# NUC200AE_v1 register map
File version: 1.0
Registers are 32-bit, read-write, reset 0x0 unless marked. A register's access mark holds for its fields unless they carry their own. Offsets are from the block's base; [hi:lo] are bit positions; 'fields as' and 'values as' point back to an identical list.

## WWDT — WWDT Register Map
Base 0x40004100
0x00 WWDTRLD wo — Window Watchdog Timer Reload Counter Register
  [31:0] WWDTRLD — WWDT Reload Counter Register. Writing 0x00005AA5 to this register will reload the WWDT counter value to 0x3F. Note: User can only write WWDTRLD to reload WWDT counter value when current WWDT counter value between 0 and WINCMP. If user writes WWDTRLD when current WWDT counter value is larger than WINCMP, WWDT reset signal will generate immediately.
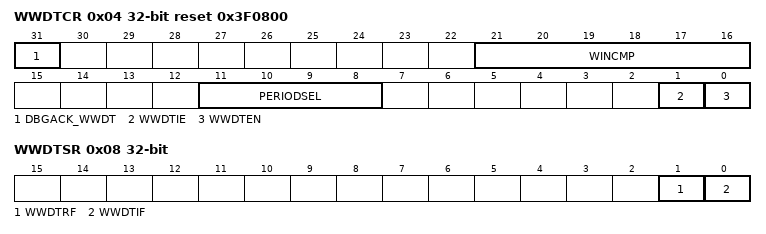
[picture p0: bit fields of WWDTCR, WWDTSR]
0x04 WWDTCR reset 0x3F0800 — Window Watchdog Timer Control Register
  [31] DBGACK_WWDT — ICE Debug Mode Acknowledge Disable Bit. WWDT down counter will keep going no matter CPU is held by ICE or not.
    0=ICE debug mode acknowledgement effects WWDT counting; 1=ICE debug mode acknowledgement Disabled
  [21:16] WINCMP — WWDT Window Compare Register. Set this register to adjust the valid reload window. Note: User can only write WWDTRLD to reload WWDT counter value when current WWDT counter value between 0 and WINCMP. If user writes WWDTRLD when current WWDT counter value larger than WINCMP, WWDT reset signal will generate immediately.
  [11:8] PERIODSEL — WWDT Counter Prescale Period Selection
    0=Pre-scale is 1; Max time-out period is 1 * 64 * TWWDT; 1=Pre-scale is 2; Max time-out period is 2 * 64 * TWWDT; 2=Pre-scale is 4; Max time-out period is 4 * 64 * TWWDT; 3=Pre-scale is 8; Max time-out period is 8 * 64 * TWWDT; 4=Pre-scale is 16; Max time-out period is 16 * 64 * TWWDT; 5=Pre-scale is 32; Max time-out period is 32 * 64 * TWWDT; 6=Pre-scale is 64; Max time-out period is 64 * 64 * TWWDT; 7=Pre-scale is 128; Max time-out period is 128 * 64 * TWWDT; 8=Pre-scale is 192; Max time-out period is 192 * 64 * TWWDT; 9=Pre-scale is 256; Max time-out period is 256 * 64 * TWWDT; 10=Pre-scale is 384; Max time-out period is 384 * 64 * TWWDT; 11=Pre-scale is 512; Max time-out period is 512 * 64 * TWWDT; 12=Pre-scale is 768; Max time-out period is 768 * 64 * TWWDT; 13=Pre-scale is 1024; Max time-out period is 1024 * 64 * TWWDT; 14=Pre-scale is 1536; Max time-out period is 1536 * 64 * TWWDT; 15=Pre-scale is 2048; Max time-out period is 2048 * 64 * TWWDT
  [1] WWDTIE — WWDT Interrupt Enable Bit. If this bit is enabled, the WWDT counter compare match interrupt signal is generated and inform to CPU.
    0=WWDT counter compare match interrupt Disabled; 1=WWDT counter compare match interrupt Enabled
  [0] WWDTEN — WWDT Enable Bit. Set this bit to enable WWDT counter counting
    0=WWDT counter is stopped; 1=WWDT counter is starting counting
0x08 WWDTSR — Window Watchdog Timer Status Register
  [1] WWDTRF — WWDT Time-Out Reset Flag. This bit indicates the system has been reset by WWDT time-out reset or not. Note: This bit is cleared by writing 1 to it.
    0=WWDT time-out reset did not occur; 1=WWDT time-out reset occurred
  [0] WWDTIF — WWDT Compare Match Interrupt Flag. This bit indicates the interrupt flag status of WWDT while WWDT counter value matches WINCMP value. Note: This bit is cleared by writing 1 to it.
    0=No effect; 1=WWDT counter value matches WINCMP value
0x0C WWDTCVR ro reset 0x3F — Window Watchdog Timer Counter Value Register
  [5:0] WWDTCVAL — WWDT Counter Value. WWDTCVAL will be updated continuously to monitor 6-bit down counter value.

## ACMP — ACMP Register Map
Base 0x400D0000
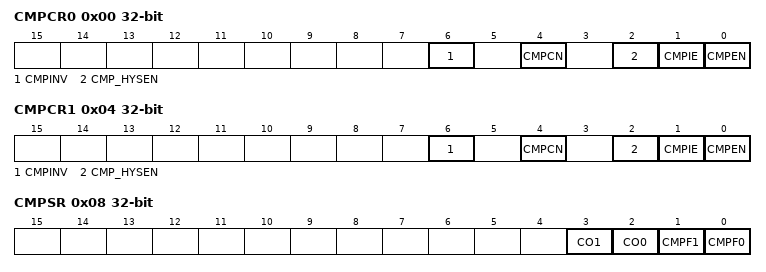
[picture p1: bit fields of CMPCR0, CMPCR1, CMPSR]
0x00 CMPCR0 — Analog Comparator 0 Control Register
  [6] CMPINV — Comparator Output Inverse Enable Bit
    0=Comparator analog output inverse is Disabled; 1=Comparator analog output inverse is Enabled
  [4] CMPCN — Comparator Negative Input Selection
    0=The source of the negative comparator input is from ACMPn_N pin (n = 0, 1); 1=Internal band-gap reference voltage is selected as the source of negative comparator input
  [2] CMP_HYSEN — Comparator Hysteresis Enable Bit
    0=Hysteresis function Disabled (Default); 1=Hysteresis function Enabled
  [1] CMPIE — Comparator Interrupt Enable Bit
    0=Interrupt function Disabled; 1=Interrupt function Enabled
  [0] CMPEN — Comparator Enable Bit
    0=Comparator Disabled; 1=Comparator Enabled
0x04 CMPCR1 — Analog Comparator 1 Control Register
  fields as CMPCR0
0x08 CMPSR — Analog Comparator Status Register
  [3] CO1 — Comparator 1 Output
  [2] CO0 — Comparator 0 Output
  [1] CMPF1 — Comparator 1 Interrupt Flag. This bit is set by hardware whenever the comparator 1 output changes state. This will cause an interrupt if CMPCR1[1] is set to 1. Write 1 to clear this bit to 0.
  [0] CMPF0 — Comparator 0 Interrupt Flag. This bit is set by hardware whenever the comparator 0 output changes state. This will cause an interrupt if CMPCR0[1] is set to 1. Write 1 to clear this bit to 0.
